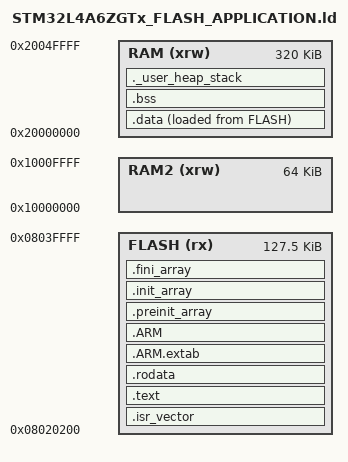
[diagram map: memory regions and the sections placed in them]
/* Entry Point */
ENTRY(Reset_Handler)

/* Stack */
_estack = ORIGIN(RAM) + LENGTH(RAM);
_Min_Heap_Size = 0x200;
_Min_Stack_Size = 0x400;

/* Memory layout */
MEMORY
{
  RAM (xrw)    : ORIGIN = 0x20000000, LENGTH = 320K
  RAM2 (xrw)   : ORIGIN = 0x10000000, LENGTH = 64K
  FLASH (rx)   : ORIGIN = 0x08020200, LENGTH = 0x1FE00 /* App code after MCUboot header */
}

/* Sections */
SECTIONS
{
  /* Startup code */
  .isr_vector :
  {
    . = ALIGN(8);
    KEEP(*(.isr_vector))
    . = ALIGN(8);
  } >FLASH

  /* Program code */
  .text :
  {
    . = ALIGN(8);
    *(.text)
    *(.text*)
    *(.glue_7)
    *(.glue_7t)
    *(.eh_frame)

    KEEP(*(.init))
    KEEP(*(.fini))

    . = ALIGN(8);
    _etext = .;
  } >FLASH

  /* Constants */
  .rodata :
  {
    . = ALIGN(8);
    *(.rodata)
    *(.rodata*)
    . = ALIGN(8);
  } >FLASH

  /* ARM sections */
  .ARM.extab :
  {
    . = ALIGN(8);
    *(.ARM.extab* .gnu.linkonce.armextab.*)
    . = ALIGN(8);
  } >FLASH

  .ARM :
  {
    . = ALIGN(8);
    __exidx_start = .;
    *(.ARM.exidx*)
    __exidx_end = .;
    . = ALIGN(8);
  } >FLASH

  /* Arrays */
  .preinit_array :
  {
    . = ALIGN(8);
    PROVIDE_HIDDEN(__preinit_array_start = .);
    KEEP(*(.preinit_array*))
    PROVIDE_HIDDEN(__preinit_array_end = .);
    . = ALIGN(8);
  } >FLASH

  .init_array :
  {
    . = ALIGN(8);
    PROVIDE_HIDDEN(__init_array_start = .);
    KEEP(*(SORT(.init_array.*)))
    KEEP(*(.init_array*))
    PROVIDE_HIDDEN(__init_array_end = .);
    . = ALIGN(8);
  } >FLASH

  .fini_array :
  {
    . = ALIGN(8);
    PROVIDE_HIDDEN(__fini_array_start = .);
    KEEP(*(SORT(.fini_array.*)))
    KEEP(*(.fini_array*))
    PROVIDE_HIDDEN(__fini_array_end = .);
    . = ALIGN(8);
  } >FLASH

  /* Initialized data */
  _sidata = LOADADDR(.data);

  .data :
  {
    . = ALIGN(8);
    _sdata = .;
    *(.data)
    *(.data*)
    . = ALIGN(8);
    _edata = .;
  } >RAM AT> FLASH

  /* Uninitialized data */
  .bss :
  {
    . = ALIGN(4);
    _sbss = .;
    __bss_start__ = _sbss;
    *(.bss)
    *(.bss*)
    *(COMMON)
    . = ALIGN(4);
    _ebss = .;
    __bss_end__ = _ebss;
  } >RAM

  /* Heap and stack */
  ._user_heap_stack :
  {
    . = ALIGN(8);
    PROVIDE(end = .);
    PROVIDE(_end = .);
    . = . + _Min_Heap_Size;
    . = . + _Min_Stack_Size;
    . = ALIGN(8);
  } >RAM

  /* Discard unused sections */
  /DISCARD/ :
  {
    libc.a(*)
    libm.a(*)
    libgcc.a(*)
  }

  .ARM.attributes 0 : { *(.ARM.attributes) }
}
